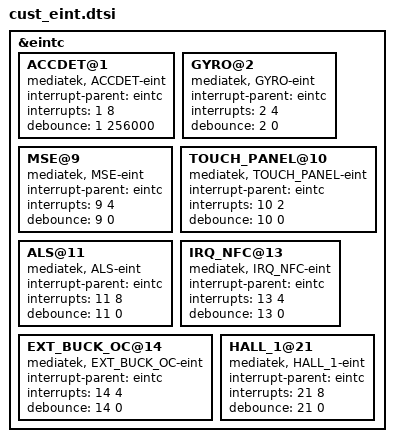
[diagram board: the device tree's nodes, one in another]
/*
 * Generated by MTK SP DrvGen Version 03.13.6 for MT6752. Copyright MediaTek Inc. (C) 2013.
 * Wed Nov 05 14:42:28 2014
 * Do Not Modify the File.
 */

/*************************
 * EINT DTSI File
*************************/

&eintc {
	ACCDET@1 {
		compatible = "mediatek, ACCDET-eint";
		interrupt-parent = <&eintc>;
		interrupts = <1 8>;
		debounce = <1 256000>;
	};

	GYRO@2 {
		compatible = "mediatek, GYRO-eint";
		interrupt-parent = <&eintc>;
		interrupts = <2 4>;
		debounce = <2 0>;
	};

	MSE@9 {
		compatible = "mediatek, MSE-eint";
		interrupt-parent = <&eintc>;
		interrupts = <9 4>;
		debounce = <9 0>;
	};

	TOUCH_PANEL@10 {
		compatible = "mediatek, TOUCH_PANEL-eint";
		interrupt-parent = <&eintc>;
		interrupts = <10 2>;
		debounce = <10 0>;
	};

	ALS@11 {
		compatible = "mediatek, ALS-eint";
		interrupt-parent = <&eintc>;
		interrupts = <11 8>;
		debounce = <11 0>;
	};

	IRQ_NFC@13 {
		compatible = "mediatek, IRQ_NFC-eint";
		interrupt-parent = <&eintc>;
		interrupts = <13 4>;
		debounce = <13 0>;
	};

	EXT_BUCK_OC@14 {
		compatible = "mediatek, EXT_BUCK_OC-eint";
		interrupt-parent = <&eintc>;
		interrupts = <14 4>;
		debounce = <14 0>;
	};

	HALL_1@21 {
		compatible = "mediatek, HALL_1-eint";
		interrupt-parent = <&eintc>;
		interrupts = <21 8>;
		debounce = <21 0>;
	};

};
